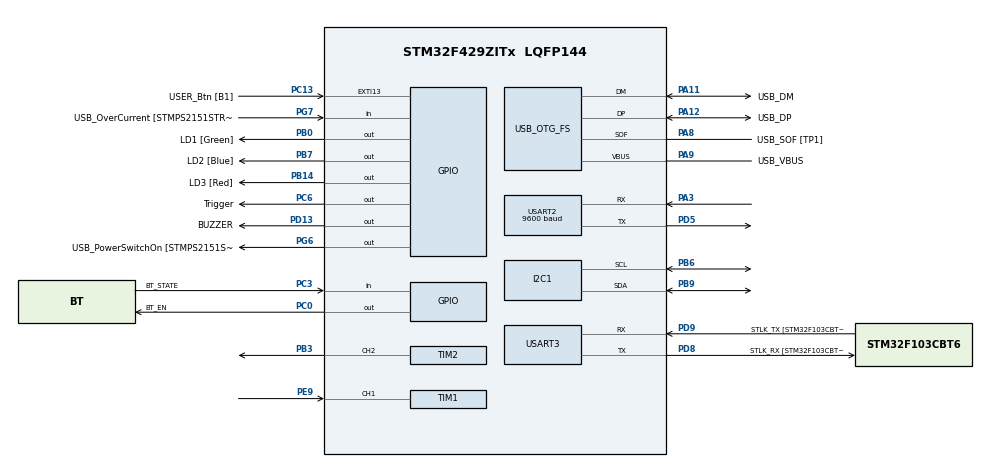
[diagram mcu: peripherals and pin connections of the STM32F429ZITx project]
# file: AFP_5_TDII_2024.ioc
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Mcu.Family=STM32F4
Mcu.Name=STM32F429ZITx
Mcu.Package=LQFP144
NVIC.PriorityGroup=NVIC_PRIORITYGROUP_4
PA10.GPIO_Label=USB_ID
PA10.Signal=USB_OTG_FS_ID
PA11.GPIO_Label=USB_DM
PA11.Mode=Device_Only
PA11.Signal=USB_OTG_FS_DM
PA12.GPIO_Label=USB_DP
PA12.Mode=Device_Only
PA12.Signal=USB_OTG_FS_DP
PA13.GPIO_Label=TMS
PA13.Mode=Serial_Wire
PA13.Signal=SYS_JTMS-SWDIO
PA14.GPIO_Label=TCK
PA14.Mode=Serial_Wire
PA14.Signal=SYS_JTCK-SWCLK
PA3.Mode=Asynchronous
PA3.Signal=USART2_RX
PA8.GPIO_Label=USB_SOF [TP1]
PA8.Mode=Activate_SOF_FS
PA8.Signal=USB_OTG_FS_SOF
PA9.GPIO_Label=USB_VBUS
PA9.Mode=Activate_VBUS
PA9.Signal=USB_OTG_FS_VBUS
PB0.GPIO_Label=LD1 [Green]
PB0.Signal=GPIO_Output
PB14.GPIO_Label=LD3 [Red]
PB14.Signal=GPIO_Output
PB3.Signal=S_TIM2_CH2
PB6.Mode=I2C
PB6.Signal=I2C1_SCL
PB7.GPIO_Label=LD2 [Blue]
PB7.Signal=GPIO_Output
PB9.Mode=I2C
PB9.Signal=I2C1_SDA
PC0.GPIO_Label=BT_EN
PC0.Signal=GPIO_Output
PC13.GPIO_Label=USER_Btn [B1]
PC13.Signal=GPXTI13
PC14/OSC32_IN.Mode=LSE-External-Oscillator
PC14/OSC32_IN.Signal=RCC_OSC32_IN
PC15/OSC32_OUT.Mode=LSE-External-Oscillator
PC15/OSC32_OUT.Signal=RCC_OSC32_OUT
PC3.GPIO_Label=BT_STATE
PC3.Signal=GPIO_Input
PC6.GPIO_Label=Trigger
PC6.GPIO_Speed=GPIO_SPEED_FREQ_LOW
PC6.Signal=GPIO_Output
PD13.GPIO_Label=BUZZER
PD13.Signal=GPIO_Output
PD5.Mode=Asynchronous
PD5.Signal=USART2_TX
PD8.GPIO_Label=STLK_RX [STM32F103CBT6_PA3]
PD8.Mode=Asynchronous
PD8.Signal=USART3_TX
PD9.GPIO_Label=STLK_TX [STM32F103CBT6_PA2]
PD9.Mode=Asynchronous
PD9.Signal=USART3_RX
PE9.Signal=S_TIM1_CH1
PG6.GPIO_Label=USB_PowerSwitchOn [STMPS2151STR_EN]
PG6.Signal=GPIO_Output
PG7.GPIO_Label=USB_OverCurrent [STMPS2151STR_FAULT]
PG7.Signal=GPIO_Input
PH0/OSC_IN.GPIO_Label=MCO [STM32F103CBT6_PA8]
PH0/OSC_IN.Mode=HSE-External-Clock-Source
PH0/OSC_IN.Signal=RCC_OSC_IN
PH1/OSC_OUT.Mode=HSE-External-Clock-Source
PH1/OSC_OUT.Signal=RCC_OSC_OUT
ProjectManager.HeapSize=0x200
ProjectManager.StackSize=0x400
ProjectManager.TargetToolchain=STM32CubeIDE
RCC.48MHZClocksFreq_Value=48000000
RCC.AHBFreq_Value=168000000
RCC.APB1CLKDivider=RCC_HCLK_DIV4
RCC.APB1Freq_Value=42000000
RCC.APB1TimFreq_Value=84000000
RCC.APB2CLKDivider=RCC_HCLK_DIV2
RCC.APB2Freq_Value=84000000
RCC.APB2TimCLKDivider=2
RCC.APB2TimFreq_Value=168000000
RCC.CortexFreq_Value=168000000
RCC.HCLKFreq_Value=168000000
RCC.HSE_VALUE=8000000
RCC.HSI_VALUE=16000000
RCC.PLLM=4
RCC.PLLMUL=RCC_PLL_MUL9
RCC.PLLN=168
RCC.PLLQ=7
RCC.PRESCALERUSB=RCC_USBCLKSOURCE_PLL_DIV1_5
RCC.SYSCLKFreq_VALUE=168000000
RCC.SYSCLKSource=RCC_SYSCLKSOURCE_PLLCLK
RCC.SYSCLKSourceVirtual=RCC_SYSCLKSOURCE_PLLCLK
RCC.USBFreq_Value=48000000
RCC.VCOOutputFreq_Value=336000000
SH.S_TIM1_CH1.0=TIM1_CH1,Input_Capture1_from_TI1
SH.S_TIM2_CH2.0=TIM2_CH2,PWM Generation2 CH2
TIM1.Channel-Input_Capture1_from_TI1=TIM_CHANNEL_1
TIM1.ICFilter_CH1=4
TIM1.Prescaler=96-1
TIM2.Channel-PWM\ Generation2\ CH2=TIM_CHANNEL_2
TIM2.Period=20000
TIM2.Prescaler=168-1
USART2.BaudRate=9600
USART2.VirtualMode=VM_ASYNC
USART3.VirtualMode=VM_ASYNC
USB_OTG_FS.VirtualMode=Device_Only
VP_TIM1_VS_ClockSourceINT.Mode=Internal
VP_TIM2_VS_ClockSourceINT.Mode=Internal
board=NUCLEO-F429ZI

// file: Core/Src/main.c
/* USER CODE BEGIN Header */
/**
  ******************************************************************************
  * @file           : main.c
  * @brief          : Main program body
  ******************************************************************************
  * @attention
  *
  * Copyright (c) 2025 STMicroelectronics.
  * All rights reserved.
  *
  * This software is licensed under terms that can be found in the LICENSE file
  * in the root directory of this software component.
  * If no LICENSE file comes with this software, it is provided AS-IS.
  *
  ******************************************************************************
  */
/* USER CODE END Header */
#include "main.h"
#include "i2c.h"
#include "tim.h"
#include "usart.h"
#include "usb_otg.h"
#include "gpio.h"

/* USER CODE BEGIN Includes */

#include "RADAR_Delay.h"
#include "RADAR_GPIO.h"
#include "RADAR_HC05.h"

/* USER CODE END Includes */

void SystemClock_Config(void);

int main(void)
{

  /* MCU Configuration--------------------------------------------------------*/

  /* Reset of all peripherals, Initializes the Flash interface and the Systick. */
  HAL_Init();

  /* Configure the system clock */
  SystemClock_Config();

  /* Initialize all configured peripherals */
  MX_GPIO_Init();
  MX_USART3_UART_Init();
  MX_USB_OTG_FS_PCD_Init();

  MX_I2C1_Init();	//LCD

  MX_TIM1_Init();	//HCSR04

  MX_TIM2_Init();	//ServoMotor PWM

  MX_USART2_UART_Init();	//Bluetooth

  /* Infinite loop */
  while (1)
  {

  }
}

void Error_Handler(void)
{
  __disable_irq();
  while (1)
  {
  }
}
